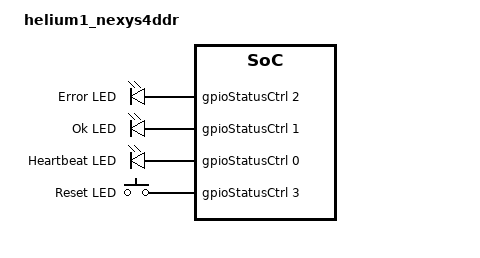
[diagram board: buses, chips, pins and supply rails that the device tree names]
/dts-v1/;
#include <helium/helium1.dtsi>

/ {
    model = "helium1_nexys4ddr";
    compatible = "elements,helium1_nexys4ddr";

    chosen {
        zephyr,console = &uartStdCtrl;
        zephyr,shell-uart = &uartStdCtrl;
        zephyr,sram = &ram0;
    };
    leds {
        compatible = "gpio-leds";
        error: ERROR {
            gpios = <&gpioStatusCtrl 2 GPIO_ACTIVE_HIGH>;
            label = "Error LED";
        };
        ok: OK {
            gpios = <&gpioStatusCtrl 1 GPIO_ACTIVE_HIGH>;
            label = "Ok LED";
        };
        heartbeat: HEARTBEAT {
            gpios = <&gpioStatusCtrl 0 GPIO_ACTIVE_HIGH>;
            label = "Heartbeat LED";
        };
    };
    keys {
        compatible = "gpio-keys";
        reset: RESET {
            gpios = <&gpioStatusCtrl 3 GPIO_ACTIVE_HIGH>;
            label = "Reset LED";
        };
    };
};
